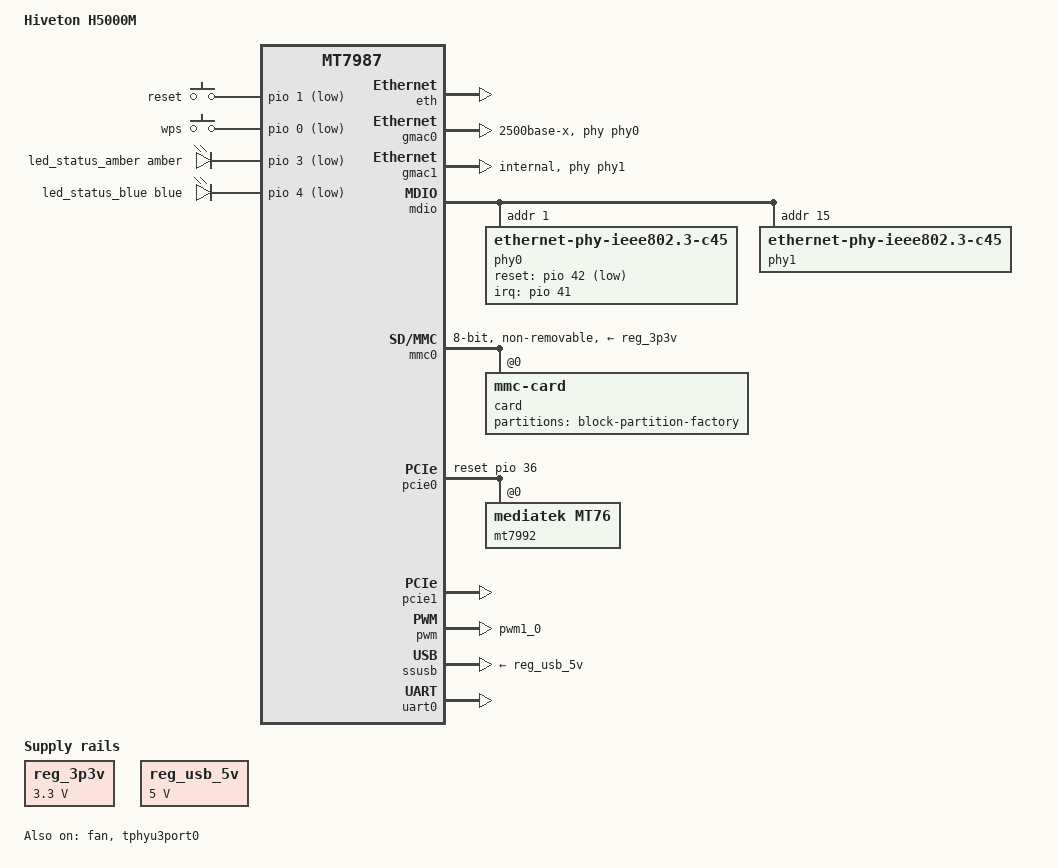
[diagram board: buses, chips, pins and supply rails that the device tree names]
// SPDX-License-Identifier: (GPL-2.0 OR MIT)

/dts-v1/;
#include "mt7987a.dtsi"
#include <dt-bindings/input/input.h>

/ {
	model = "Hiveton H5000M";
	compatible = "hiveton,h5000m", "mediatek,mt7987a", "mediatek,mt7987";

	aliases {
		led-boot = &led_status_blue;
		led-failsafe = &led_status_amber;
		led-upgrade = &led_status_amber;
		serial0 = &uart0;
	};

	chosen {
		bootargs = "earlycon=uart8250,mmio32,0x11000000 \
			    root=PARTLABEL=rootfs rootwait pci=pcie_bus_perf";
		stdout-path = "serial0:115200n8";
	};

	gpio-keys {
		compatible = "gpio-keys";

		button-reset {
			label = "reset";
			linux,code = <KEY_RESTART>;
			gpios = <&pio 1 GPIO_ACTIVE_LOW>;
			debounce-interval = <10>;
		};

		button-wps {
			label = "wps";
			linux,code = <KEY_WPS_BUTTON>;
			gpios = <&pio 0 GPIO_ACTIVE_LOW>;
			debounce-interval = <10>;
		};
	};

	/*
	 * LED Indicator Layout
	 * -------------------
	 * Total of 5 LED indicators, viewed from front with antenna facing up (left to right):
	 *
	 * LED 1: 5G Module indicator
	 * LED 2: Built-in 2.5G Ethernet port indicator (configurable in system)
	 * LED 3: User-definable (configurable in system)
	 * LED 4: User-definable (configurable in system)
	 * LED 5: Power indicator
	 *
	 * Note:
	 * - LEDs 1 and 5 are hardware-controlled and cannot be modified via software
	 * - In vendor firmware, LEDs 3 and 4 are used as WiFi link activity indicators
	 *   for dual-band (2.4GHz/5GHz) respectively
	 */
	leds {
		compatible = "gpio-leds";

		led_status_amber: led-3 {
			function = LED_FUNCTION_WLAN_2GHZ;
			color = <LED_COLOR_ID_AMBER>;
			gpios = <&pio 3 GPIO_ACTIVE_LOW>;
		};

		led_status_blue: led-4 {
			function = LED_FUNCTION_WLAN_5GHZ;
			color = <LED_COLOR_ID_BLUE>;
			gpios = <&pio 4 GPIO_ACTIVE_LOW>;
		};
	};

	reg_3p3v: regulator-3p3v {
		compatible = "regulator-fixed";
		regulator-name = "fixed-3.3V";
		regulator-min-microvolt = <3300000>;
		regulator-max-microvolt = <3300000>;
		regulator-boot-on;
		regulator-always-on;
	};

	reg_usb_5v: regulator-usb-5v {
		compatible = "regulator-fixed";
		regulator-name = "usb-5v";
		regulator-max-microvolt = <5000000>;
		regulator-min-microvolt = <5000000>;
		regulator-boot-on;
		regulator-always-on;
	};
};

&eth {
	status = "okay";
};

&fan {
	pwms = <&pwm 1 50000 0>;
	status = "okay";
};

/*
 * Fan policy is managed by h5000m-fancontrol (systemd service). Keep the CPU
 * frequency cooling, hot and critical trips intact, but prevent the thermal
 * governor from racing userspace for the same PWM output.
 */
&{/thermal-zones/cpu-thermal/cooling-maps} {
	/delete-node/ cpu-active-high;
	/delete-node/ cpu-active-low;
	/delete-node/ cpu-passive;
};

/*
 * 【为什么这里不再写死 mac-address】
 * 原先两个 gmac 各写了一个固定值（...:84 / ...:85）。同一个固件刷到多台
 * 设备上，每台机器的 eth0/eth1 就都是同一个 MAC —— 两台设备插进同一个
 * 二层网络（上游光猫、交换机、园区网）就会 MAC 漂移/冲突，表现是时断时续、
 * ARP 表抖动，现场极难定位。MT7987 也没有把出厂 MAC 放在能被内核直接读到的
 * nvmem/OTP 里，所以这里不写死，交给用户空间按每块板子的 eMMC CID 派生：
 * 见 /usr/local/sbin/h5000m-router-init.sh 的 derive_board_macs()。
 * 派生出来的 MAC 落在 02:xx:xx:00:00:xx（本地管理、单播），并通过
 * NetworkManager 的 ethernet.cloned-mac-address 持久化应用。
 */
&gmac0 {
	phy-mode = "2500base-x";
	phy-handle = <&phy0>;
	status = "okay";
};

&gmac1 {
	phy-mode = "internal";
	phy-handle = <&phy1>;
	status = "okay";
};

&mdio {
	/* RTL8221B-VB-CG 2.5Gbps PHY (away from power) eth0 */
	phy0: phy@1 {
		compatible = "ethernet-phy-ieee802.3-c45";
		reg = <1>;
		reset-gpios = <&pio 42 GPIO_ACTIVE_LOW>;
		reset-assert-us = <100000>;
		reset-deassert-us = <100000>;
		interrupt-parent = <&pio>;
		interrupts = <41 IRQ_TYPE_LEVEL_LOW>;
		realtek,aldps-enable;
	};

	/* built-in 2.5G Ethernet PHY (near power) eth1 */
	phy1: phy@15 {
		compatible = "ethernet-phy-ieee802.3-c45";
		reg = <15>;
		pinctrl-names = "i2p5gbe-led";
		pinctrl-0 = <&i2p5gbe_led0_pins>;

		leds {
			#address-cells = <1>;
			#size-cells = <0>;

			led@0 {
				reg = <0>;
				function = LED_FUNCTION_WAN;
				color = <LED_COLOR_ID_RED>;
			};
		};
	};
};

&mmc0 {
	pinctrl-names = "default", "state_uhs";
	pinctrl-0 = <&mmc_pins_default>;
	pinctrl-1 = <&mmc_pins_uhs>;
	bus-width = <8>;
	/*
	 * 2026-10-09 降频规避「msdc 写挂死」。
	 *
	 * 实机串口实证（boot-20261009-073542.log）：48MHz 下首个致命超时是
	 * CMD18 读取，随后卡不再响应恢复命令。后续可见：
	 *   CMD6 arg=0x03200101 → EXT_CSD[32]=1    FLUSH_CACHE
	 *   CMD6 arg=0x03B34801 → EXT_CSD[179]=0x48 PARTITION_CONFIG
	 * 第二个命令恢复用户数据分区的选择，不能误判为 BKOPS。故日志证明的是
	 * eMMC 通讯链路失效，不能仅据此归因到写入路径。
	 * 随后升级为 mmc0: cache flush error -110、tried to HW reset card -110，
	 * 直至 mmcblk0: recovery failed!；回写线程 flush-179:0 被封死在 mmc_blk_rw_wait，
	 * CPU3 软中断冻结拖垮 RCU，全系统在同一启动内冻结。
	 *
	 * 降到 25MHz 以增大 CMD/DATA 线的采样时序余量。单变量对照：本轮只改频率，
	 * 保留 cap-mmc-highspeed（仍走 high speed 时序、仅限时钟），便于隔离「频率」
	 * 与「时序模式」两个变量。若 25MHz 无效，下一步再去掉 cap-mmc-highspeed
	 * 退回 default speed。
	 */
	max-frequency = <25000000>;
	cap-mmc-highspeed;
	vmmc-supply = <&reg_3p3v>;
	/* 这是焊接式 eMMC；禁止无意义的 SD / SDIO 探测命令。 */
	no-sd;
	no-sdio;
	non-removable;
	status = "okay";

	card@0 {
		compatible = "mmc-card";
		reg = <0>;

		block {
			compatible = "block-device";

			partitions {
				block-partition-factory {
					partname = "factory";

					nvmem-layout {
						compatible = "fixed-layout";
						#address-cells = <1>;
						#size-cells = <1>;

						eeprom_factory_0: eeprom@0 {
							reg = <0x0 0x1e00>;
						};
					};
				};
			};
		};
	};
};

&pcie0 {
	pinctrl-names = "default";
	pinctrl-0 = <&pcie0_pins>;
	reset-gpios = <&pio 36 GPIO_ACTIVE_HIGH>;
	status = "okay";

	pcie@0,0 {
		reg = <0x0000 0 0 0 0>;
		#address-cells = <3>;
		#size-cells = <2>;
		device_type = "pci";

		mt7992@0,0 {
			compatible = "mediatek,mt76";
			reg = <0x0000 0 0 0 0>;

			nvmem-cells = <&eeprom_factory_0>;
			nvmem-cell-names = "eeprom";

			#address-cells = <1>;
			#size-cells = <0>;

			ieee80211-freq-limit = <2400000 2500000>,
					       <5170000 5835000>;
		};
	};
};

&pcie1 {
	/* 与已验证镜像的 DTB 保持一致（该槽位未挂设备，启用无副作用） */
	status = "okay";
};

&pio {
	pwm_fan_pins: pwm-fan-pins {
		mux {
			function = "pwm";
			groups = "pwm1_0";
		};
	};
};

&pwm {
	status = "okay";
	pinctrl-names = "default";
	pinctrl-0 = <&pwm_fan_pins>;
};

&ssusb {
	status = "okay";
	vusb33-supply = <&reg_3p3v>;
	vbus-supply = <&reg_usb_5v>;
};

&tphyu3port0 {
	status = "okay";
};

&uart0 {
	pinctrl-names = "default";
	pinctrl-0 = <&uart0_pins>;
	status = "okay";
};
